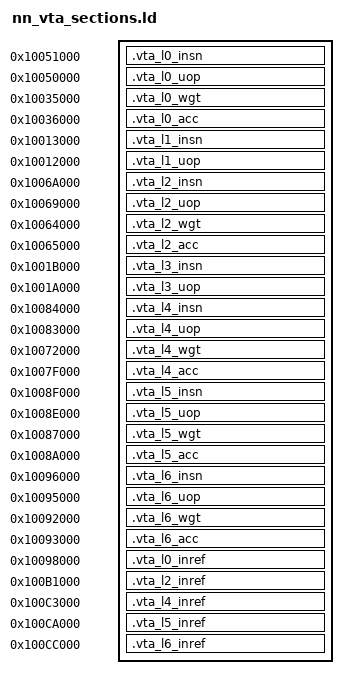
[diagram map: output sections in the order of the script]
/* Auto-generated by the VTA baremetal codegen - DO NOT EDIT        */
/* VTA static model data linker fragment                             */
/*                                                                   */
/* Include this file inside the platform linker script generated.                    */
/* Example (in your lscript.ld):           */
/*   INCLUDE ../gen/nn_vta_sections.ld                                */

SECTIONS {
.vta_l0_insn 0x10051000 : { KEEP(*(.vta_l0_insn)) }
.vta_l0_uop 0x10050000 : { KEEP(*(.vta_l0_uop)) }
.vta_l0_wgt 0x10035000 : { KEEP(*(.vta_l0_wgt)) }
.vta_l0_acc 0x10036000 : { KEEP(*(.vta_l0_acc)) }
.vta_l1_insn 0x10013000 : { KEEP(*(.vta_l1_insn)) }
.vta_l1_uop 0x10012000 : { KEEP(*(.vta_l1_uop)) }
.vta_l2_insn 0x1006A000 : { KEEP(*(.vta_l2_insn)) }
.vta_l2_uop 0x10069000 : { KEEP(*(.vta_l2_uop)) }
.vta_l2_wgt 0x10064000 : { KEEP(*(.vta_l2_wgt)) }
.vta_l2_acc 0x10065000 : { KEEP(*(.vta_l2_acc)) }
.vta_l3_insn 0x1001B000 : { KEEP(*(.vta_l3_insn)) }
.vta_l3_uop 0x1001A000 : { KEEP(*(.vta_l3_uop)) }
.vta_l4_insn 0x10084000 : { KEEP(*(.vta_l4_insn)) }
.vta_l4_uop 0x10083000 : { KEEP(*(.vta_l4_uop)) }
.vta_l4_wgt 0x10072000 : { KEEP(*(.vta_l4_wgt)) }
.vta_l4_acc 0x1007F000 : { KEEP(*(.vta_l4_acc)) }
.vta_l5_insn 0x1008F000 : { KEEP(*(.vta_l5_insn)) }
.vta_l5_uop 0x1008E000 : { KEEP(*(.vta_l5_uop)) }
.vta_l5_wgt 0x10087000 : { KEEP(*(.vta_l5_wgt)) }
.vta_l5_acc 0x1008A000 : { KEEP(*(.vta_l5_acc)) }
.vta_l6_insn 0x10096000 : { KEEP(*(.vta_l6_insn)) }
.vta_l6_uop 0x10095000 : { KEEP(*(.vta_l6_uop)) }
.vta_l6_wgt 0x10092000 : { KEEP(*(.vta_l6_wgt)) }
.vta_l6_acc 0x10093000 : { KEEP(*(.vta_l6_acc)) }
.vta_l0_inref 0x10098000 : { KEEP(*(.vta_l0_inref)) }
.vta_l2_inref 0x100B1000 : { KEEP(*(.vta_l2_inref)) }
.vta_l4_inref 0x100C3000 : { KEEP(*(.vta_l4_inref)) }
.vta_l5_inref 0x100CA000 : { KEEP(*(.vta_l5_inref)) }
.vta_l6_inref 0x100CC000 : { KEEP(*(.vta_l6_inref)) }
}
